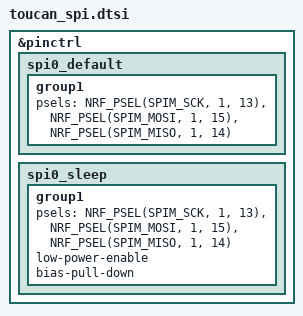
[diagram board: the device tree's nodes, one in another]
/* Shared SPIM0 pinctrl for left (display) and right (Cirque). */

&pinctrl {
	spi0_default: spi0_default {
		group1 {
			psels = <NRF_PSEL(SPIM_SCK, 1, 13)>,
				<NRF_PSEL(SPIM_MOSI, 1, 15)>,
				<NRF_PSEL(SPIM_MISO, 1, 14)>;
		};
	};

	spi0_sleep: spi0_sleep {
		group1 {
			psels = <NRF_PSEL(SPIM_SCK, 1, 13)>,
				<NRF_PSEL(SPIM_MOSI, 1, 15)>,
				<NRF_PSEL(SPIM_MISO, 1, 14)>;
			low-power-enable;
			bias-pull-down;
		};
	};
};
